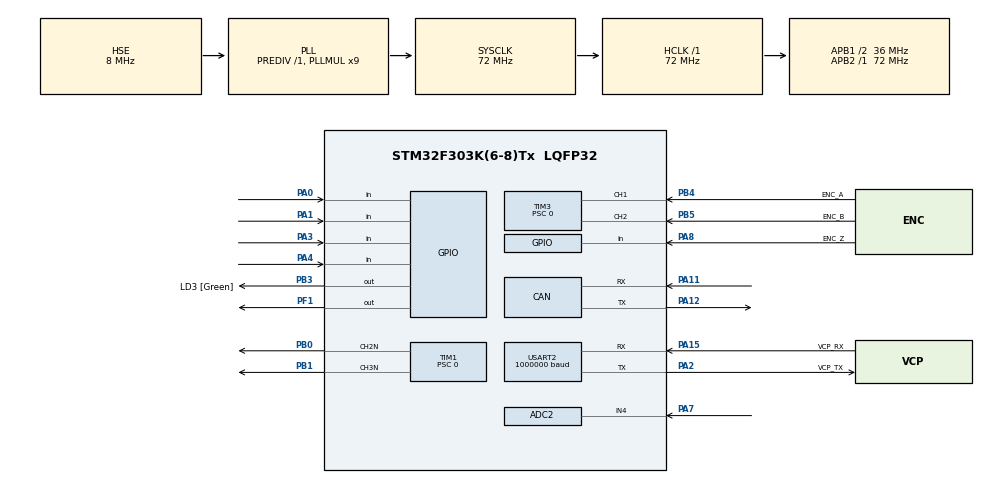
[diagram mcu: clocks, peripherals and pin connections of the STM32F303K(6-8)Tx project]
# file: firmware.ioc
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ADC2.Channel-6\#ChannelRegularConversion=ADC_CHANNEL_4
ADC2.NbrOfConversionFlag=1
ADC2.Offset-6\#ChannelRegularConversion=0
ADC2.OffsetNumber-6\#ChannelRegularConversion=ADC_OFFSET_NONE
ADC2.Rank-6\#ChannelRegularConversion=1
ADC2.SamplingTime-6\#ChannelRegularConversion=ADC_SAMPLETIME_1CYCLE_5
ADC2.SubFamily=STM32F303x8
CAN.BS1=CAN_BS1_1TQ
CAN.BS2=CAN_BS2_1TQ
CAN.CalculateTimeQuantum=444.44444444444446
Dma.Request0=USART2_RX
Dma.USART2_RX.0.Direction=DMA_PERIPH_TO_MEMORY
Dma.USART2_RX.0.Instance=DMA1_Channel6
Dma.USART2_RX.0.MemDataAlignment=DMA_MDATAALIGN_BYTE
Dma.USART2_RX.0.MemInc=DMA_MINC_ENABLE
Dma.USART2_RX.0.Mode=DMA_CIRCULAR
Dma.USART2_RX.0.PeriphDataAlignment=DMA_PDATAALIGN_BYTE
Dma.USART2_RX.0.PeriphInc=DMA_PINC_DISABLE
Dma.USART2_RX.0.Priority=DMA_PRIORITY_LOW
Mcu.Family=STM32F3
Mcu.Name=STM32F303K(6-8)Tx
Mcu.Package=LQFP32
NVIC.DMA1_Channel6_IRQn=true\:0\:0\:false\:false\:true\:false
NVIC.PriorityGroup=NVIC_PRIORITYGROUP_4
PA0.Signal=GPIO_Input
PA1.Signal=GPIO_Input
PA11.Mode=Master
PA11.Signal=CAN_RX
PA12.Mode=Master
PA12.Signal=CAN_TX
PA13.GPIO_Label=SWDIO
PA13.Mode=Serial_Wire
PA13.Signal=SYS_JTMS-SWDIO
PA14.GPIO_Label=SWCLK
PA14.Mode=Serial_Wire
PA14.Signal=SYS_JTCK-SWCLK
PA15.GPIO_Label=VCP_RX
PA15.Mode=Asynchronous
PA15.Signal=USART2_RX
PA2.GPIO_Label=VCP_TX
PA2.Mode=Asynchronous
PA2.Signal=USART2_TX
PA3.Signal=GPIO_Input
PA4.Signal=GPIO_Input
PA7.Mode=IN4-Single-Ended
PA7.Signal=ADC2_IN4
PA8.GPIO_Label=ENC_Z
PA8.Signal=GPIO_Input
PB0.Mode=PWM Generation2 CH2N
PB0.Signal=TIM1_CH2N
PB1.Mode=PWM Generation3 CH3N
PB1.Signal=TIM1_CH3N
PB3.GPIO_Label=LD3 [Green]
PB3.Signal=GPIO_Output
PB4.GPIO_Label=ENC_A
PB4.GPIO_PuPd=GPIO_PULLUP
PB4.Signal=S_TIM3_CH1
PB5.GPIO_Label=ENC_B
PB5.GPIO_PuPd=GPIO_PULLUP
PB5.Signal=S_TIM3_CH2
PF0\ /\ OSC_IN.GPIO_Label=MCO
PF0\ /\ OSC_IN.Mode=HSE-External-Clock-Source
PF0\ /\ OSC_IN.Signal=RCC_OSC_IN
PF1\ /\ OSC_OUT.PinState=GPIO_PIN_SET
PF1\ /\ OSC_OUT.Signal=GPIO_Output
ProjectManager.HeapSize=0x200
ProjectManager.StackSize=0x400
ProjectManager.TargetToolchain=Makefile
RCC.AHBFreq_Value=72000000
RCC.APB1CLKDivider=RCC_HCLK_DIV2
RCC.APB1Freq_Value=36000000
RCC.APB1TimFreq_Value=72000000
RCC.APB2Freq_Value=72000000
RCC.APB2TimFreq_Value=72000000
RCC.CortexFreq_Value=72000000
RCC.EnbaleCSS=true
RCC.HCLKFreq_Value=72000000
RCC.HSE_VALUE=8000000
RCC.HSI_VALUE=8000000
RCC.PLLMUL=RCC_PLL_MUL9
RCC.PLLSourceVirtual=RCC_PLLSOURCE_HSE
RCC.SYSCLKFreq_VALUE=72000000
RCC.SYSCLKSourceVirtual=RCC_SYSCLKSOURCE_PLLCLK
SH.S_TIM3_CH1.0=TIM3_CH1,Encoder_Interface
SH.S_TIM3_CH2.0=TIM3_CH2,Encoder_Interface
TIM1.Channel-PWM\ Generation2\ CH2N=TIM_CHANNEL_2
TIM1.Channel-PWM\ Generation3\ CH3N=TIM_CHANNEL_3
TIM1.Period=7199
TIM1.Prescaler=0
TIM3.EncoderMode=TIM_ENCODERMODE_TI12
TIM3.Period=65535
TIM3.Prescaler=0
USART2.BaudRate=1000000
USART2.DMADisableonRxErrorParam=UART_ADVFEATURE_DMA_DISABLEONRXERROR
USART2.OverSampling=UART_OVERSAMPLING_8
USART2.OverrunDisableParam=UART_ADVFEATURE_OVERRUN_DISABLE
USART2.VirtualMode-Asynchronous=VM_ASYNC
VP_TIM1_VS_ClockSourceINT.Mode=Internal
board=NUCLEO-F303K8

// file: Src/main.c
/* USER CODE BEGIN Header */
/**
  ******************************************************************************
  * @file           : main.c
  * @brief          : Main program body
  ******************************************************************************
  ** This notice applies to any and all portions of this file
  * that are not between comment pairs USER CODE BEGIN and
  * USER CODE END. Other portions of this file, whether
  * inserted by the user or by software development tools
  * are owned by their respective copyright owners.
  *
  * COPYRIGHT(c) 2018 STMicroelectronics
  *
  * Redistribution and use in source and binary forms, with or without modification,
  * are permitted provided that the following conditions are met:
  *   1. Redistributions of source code must retain the above copyright notice,
  *      this list of conditions and the following disclaimer.
  *   2. Redistributions in binary form must reproduce the above copyright notice,
  *      this list of conditions and the following disclaimer in the documentation
  *      and/or other materials provided with the distribution.
  *   3. Neither the name of STMicroelectronics nor the names of its contributors
  *      may be used to endorse or promote products derived from this software
  *      without specific prior written permission.
  *
  * THIS SOFTWARE IS PROVIDED BY THE COPYRIGHT HOLDERS AND CONTRIBUTORS "AS IS"
  * AND ANY EXPRESS OR IMPLIED WARRANTIES, INCLUDING, BUT NOT LIMITED TO, THE
  * IMPLIED WARRANTIES OF MERCHANTABILITY AND FITNESS FOR A PARTICULAR PURPOSE ARE
  * DISCLAIMED. IN NO EVENT SHALL THE COPYRIGHT HOLDER OR CONTRIBUTORS BE LIABLE
  * FOR ANY DIRECT, INDIRECT, INCIDENTAL, SPECIAL, EXEMPLARY, OR CONSEQUENTIAL
  * DAMAGES (INCLUDING, BUT NOT LIMITED TO, PROCUREMENT OF SUBSTITUTE GOODS OR
  * SERVICES; LOSS OF USE, DATA, OR PROFITS; OR BUSINESS INTERRUPTION) HOWEVER
  * CAUSED AND ON ANY THEORY OF LIABILITY, WHETHER IN CONTRACT, STRICT LIABILITY,
  * OR TORT (INCLUDING NEGLIGENCE OR OTHERWISE) ARISING IN ANY WAY OUT OF THE USE
  * OF THIS SOFTWARE, EVEN IF ADVISED OF THE POSSIBILITY OF SUCH DAMAGE.
  *
  ******************************************************************************
  */
/* USER CODE END Header */

#include "main.h"

/* USER CODE BEGIN Includes */
#include "user_main.h"

/* USER CODE END Includes */

ADC_HandleTypeDef hadc2;

CAN_HandleTypeDef hcan;

TIM_HandleTypeDef htim1;
TIM_HandleTypeDef htim3;

UART_HandleTypeDef huart2;
DMA_HandleTypeDef hdma_usart2_rx;

void SystemClock_Config(void);
static void MX_GPIO_Init(void);
static void MX_DMA_Init(void);
static void MX_USART2_UART_Init(void);
static void MX_TIM3_Init(void);
static void MX_CAN_Init(void);
static void MX_TIM1_Init(void);
static void MX_ADC2_Init(void);

int main(void)
{

  /* MCU Configuration--------------------------------------------------------*/

  /* Reset of all peripherals, Initializes the Flash interface and the Systick. */
  HAL_Init();

  /* Configure the system clock */
  SystemClock_Config();

  /* Initialize all configured peripherals */
  MX_GPIO_Init();
  MX_DMA_Init();
  MX_USART2_UART_Init();
  MX_TIM3_Init();
  MX_CAN_Init();
  MX_TIM1_Init();
  MX_ADC2_Init();
  /* USER CODE BEGIN 2 */
  setup();

  /* USER CODE END 2 */

  /* Infinite loop */
  /* USER CODE BEGIN WHILE */
  while (1)
  {
    loop();
    /* USER CODE END WHILE */

  }
}

void SystemClock_Config(void)
{
  RCC_OscInitTypeDef RCC_OscInitStruct = {0};
  RCC_ClkInitTypeDef RCC_ClkInitStruct = {0};
  RCC_PeriphCLKInitTypeDef PeriphClkInit = {0};

  /**Initializes the CPU, AHB and APB busses clocks
  */
  RCC_OscInitStruct.OscillatorType = RCC_OSCILLATORTYPE_HSE;
  RCC_OscInitStruct.HSEState = RCC_HSE_BYPASS;
  RCC_OscInitStruct.HSEPredivValue = RCC_HSE_PREDIV_DIV1;
  RCC_OscInitStruct.HSIState = RCC_HSI_ON;
  RCC_OscInitStruct.PLL.PLLState = RCC_PLL_ON;
  RCC_OscInitStruct.PLL.PLLSource = RCC_PLLSOURCE_HSE;
  RCC_OscInitStruct.PLL.PLLMUL = RCC_PLL_MUL9;
  if (HAL_RCC_OscConfig(&RCC_OscInitStruct) != HAL_OK)
  {
    Error_Handler();
  }
  /**Initializes the CPU, AHB and APB busses clocks
  */
  RCC_ClkInitStruct.ClockType = RCC_CLOCKTYPE_HCLK|RCC_CLOCKTYPE_SYSCLK
                              |RCC_CLOCKTYPE_PCLK1|RCC_CLOCKTYPE_PCLK2;
  RCC_ClkInitStruct.SYSCLKSource = RCC_SYSCLKSOURCE_PLLCLK;
  RCC_ClkInitStruct.AHBCLKDivider = RCC_SYSCLK_DIV1;
  RCC_ClkInitStruct.APB1CLKDivider = RCC_HCLK_DIV2;
  RCC_ClkInitStruct.APB2CLKDivider = RCC_HCLK_DIV1;

  if (HAL_RCC_ClockConfig(&RCC_ClkInitStruct, FLASH_LATENCY_2) != HAL_OK)
  {
    Error_Handler();
  }
  PeriphClkInit.PeriphClockSelection = RCC_PERIPHCLK_TIM1|RCC_PERIPHCLK_ADC12;
  PeriphClkInit.Adc12ClockSelection = RCC_ADC12PLLCLK_DIV1;
  PeriphClkInit.Tim1ClockSelection = RCC_TIM1CLK_HCLK;
  if (HAL_RCCEx_PeriphCLKConfig(&PeriphClkInit) != HAL_OK)
  {
    Error_Handler();
  }
  /**Enables the Clock Security System
  */
  HAL_RCC_EnableCSS();
}

static void MX_ADC2_Init(void)
{

  ADC_ChannelConfTypeDef sConfig = {0};

  /**Common config
  */
  hadc2.Instance = ADC2;
  hadc2.Init.ClockPrescaler = ADC_CLOCK_ASYNC_DIV1;
  hadc2.Init.Resolution = ADC_RESOLUTION_12B;
  hadc2.Init.ScanConvMode = ADC_SCAN_DISABLE;
  hadc2.Init.ContinuousConvMode = DISABLE;
  hadc2.Init.DiscontinuousConvMode = DISABLE;
  hadc2.Init.ExternalTrigConvEdge = ADC_EXTERNALTRIGCONVEDGE_NONE;
  hadc2.Init.ExternalTrigConv = ADC_SOFTWARE_START;
  hadc2.Init.DataAlign = ADC_DATAALIGN_RIGHT;
  hadc2.Init.NbrOfConversion = 1;
  hadc2.Init.DMAContinuousRequests = DISABLE;
  hadc2.Init.EOCSelection = ADC_EOC_SINGLE_CONV;
  hadc2.Init.LowPowerAutoWait = DISABLE;
  hadc2.Init.Overrun = ADC_OVR_DATA_OVERWRITTEN;
  if (HAL_ADC_Init(&hadc2) != HAL_OK)
  {
    Error_Handler();
  }
  /**Configure Regular Channel
  */
  sConfig.Channel = ADC_CHANNEL_4;
  sConfig.Rank = ADC_REGULAR_RANK_1;
  sConfig.SingleDiff = ADC_SINGLE_ENDED;
  sConfig.SamplingTime = ADC_SAMPLETIME_1CYCLE_5;
  sConfig.OffsetNumber = ADC_OFFSET_NONE;
  sConfig.Offset = 0;
  if (HAL_ADC_ConfigChannel(&hadc2, &sConfig) != HAL_OK)
  {
    Error_Handler();
  }

}

static void MX_CAN_Init(void)
{

  hcan.Instance = CAN;
  hcan.Init.Prescaler = 16;
  hcan.Init.Mode = CAN_MODE_NORMAL;
  hcan.Init.SyncJumpWidth = CAN_SJW_1TQ;
  hcan.Init.TimeSeg1 = CAN_BS1_1TQ;
  hcan.Init.TimeSeg2 = CAN_BS2_1TQ;
  hcan.Init.TimeTriggeredMode = DISABLE;
  hcan.Init.AutoBusOff = DISABLE;
  hcan.Init.AutoWakeUp = DISABLE;
  hcan.Init.AutoRetransmission = DISABLE;
  hcan.Init.ReceiveFifoLocked = DISABLE;
  hcan.Init.TransmitFifoPriority = DISABLE;
  if (HAL_CAN_Init(&hcan) != HAL_OK)
  {
    Error_Handler();
  }

}

static void MX_TIM1_Init(void)
{

  TIM_ClockConfigTypeDef sClockSourceConfig = {0};
  TIM_MasterConfigTypeDef sMasterConfig = {0};
  TIM_OC_InitTypeDef sConfigOC = {0};
  TIM_BreakDeadTimeConfigTypeDef sBreakDeadTimeConfig = {0};

  htim1.Instance = TIM1;
  htim1.Init.Prescaler = 1;
  htim1.Init.CounterMode = TIM_COUNTERMODE_UP;
  htim1.Init.Period = 35999;
  htim1.Init.ClockDivision = TIM_CLOCKDIVISION_DIV1;
  htim1.Init.RepetitionCounter = 0;
  htim1.Init.AutoReloadPreload = TIM_AUTORELOAD_PRELOAD_ENABLE;
  if (HAL_TIM_Base_Init(&htim1) != HAL_OK)
  {
    Error_Handler();
  }
  sClockSourceConfig.ClockSource = TIM_CLOCKSOURCE_INTERNAL;
  if (HAL_TIM_ConfigClockSource(&htim1, &sClockSourceConfig) != HAL_OK)
  {
    Error_Handler();
  }
  if (HAL_TIM_PWM_Init(&htim1) != HAL_OK)
  {
    Error_Handler();
  }
  sMasterConfig.MasterOutputTrigger = TIM_TRGO_RESET;
  sMasterConfig.MasterOutputTrigger2 = TIM_TRGO2_RESET;
  sMasterConfig.MasterSlaveMode = TIM_MASTERSLAVEMODE_DISABLE;
  if (HAL_TIMEx_MasterConfigSynchronization(&htim1, &sMasterConfig) != HAL_OK)
  {
    Error_Handler();
  }
  sConfigOC.OCMode = TIM_OCMODE_PWM1;
  sConfigOC.Pulse = 0;
  sConfigOC.OCPolarity = TIM_OCPOLARITY_HIGH;
  sConfigOC.OCNPolarity = TIM_OCNPOLARITY_HIGH;
  sConfigOC.OCFastMode = TIM_OCFAST_DISABLE;
  sConfigOC.OCIdleState = TIM_OCIDLESTATE_RESET;
  sConfigOC.OCNIdleState = TIM_OCNIDLESTATE_RESET;
  if (HAL_TIM_PWM_ConfigChannel(&htim1, &sConfigOC, TIM_CHANNEL_2) != HAL_OK)
  {
    Error_Handler();
  }
  if (HAL_TIM_PWM_ConfigChannel(&htim1, &sConfigOC, TIM_CHANNEL_3) != HAL_OK)
  {
    Error_Handler();
  }
  sBreakDeadTimeConfig.OffStateRunMode = TIM_OSSR_DISABLE;
  sBreakDeadTimeConfig.OffStateIDLEMode = TIM_OSSI_DISABLE;
  sBreakDeadTimeConfig.LockLevel = TIM_LOCKLEVEL_OFF;
  sBreakDeadTimeConfig.DeadTime = 0;
  sBreakDeadTimeConfig.BreakState = TIM_BREAK_DISABLE;
  sBreakDeadTimeConfig.BreakPolarity = TIM_BREAKPOLARITY_HIGH;
  sBreakDeadTimeConfig.BreakFilter = 0;
  sBreakDeadTimeConfig.Break2State = TIM_BREAK2_DISABLE;
  sBreakDeadTimeConfig.Break2Polarity = TIM_BREAK2POLARITY_HIGH;
  sBreakDeadTimeConfig.Break2Filter = 0;
  sBreakDeadTimeConfig.AutomaticOutput = TIM_AUTOMATICOUTPUT_DISABLE;
  if (HAL_TIMEx_ConfigBreakDeadTime(&htim1, &sBreakDeadTimeConfig) != HAL_OK)
  {
    Error_Handler();
  }
  HAL_TIM_MspPostInit(&htim1);

}

static void MX_TIM3_Init(void)
{

  TIM_Encoder_InitTypeDef sConfig = {0};
  TIM_MasterConfigTypeDef sMasterConfig = {0};

  htim3.Instance = TIM3;
  htim3.Init.Prescaler = 0;
  htim3.Init.CounterMode = TIM_COUNTERMODE_UP;
  htim3.Init.Period = 65535;
  htim3.Init.ClockDivision = TIM_CLOCKDIVISION_DIV1;
  htim3.Init.AutoReloadPreload = TIM_AUTORELOAD_PRELOAD_DISABLE;
  sConfig.EncoderMode = TIM_ENCODERMODE_TI12;
  sConfig.IC1Polarity = TIM_ICPOLARITY_RISING;
  sConfig.IC1Selection = TIM_ICSELECTION_DIRECTTI;
  sConfig.IC1Prescaler = TIM_ICPSC_DIV1;
  sConfig.IC1Filter = 0;
  sConfig.IC2Polarity = TIM_ICPOLARITY_RISING;
  sConfig.IC2Selection = TIM_ICSELECTION_DIRECTTI;
  sConfig.IC2Prescaler = TIM_ICPSC_DIV1;
  sConfig.IC2Filter = 0;
  if (HAL_TIM_Encoder_Init(&htim3, &sConfig) != HAL_OK)
  {
    Error_Handler();
  }
  sMasterConfig.MasterOutputTrigger = TIM_TRGO_RESET;
  sMasterConfig.MasterSlaveMode = TIM_MASTERSLAVEMODE_DISABLE;
  if (HAL_TIMEx_MasterConfigSynchronization(&htim3, &sMasterConfig) != HAL_OK)
  {
    Error_Handler();
  }

}

static void MX_USART2_UART_Init(void)
{

  huart2.Instance = USART2;
  huart2.Init.BaudRate = 1000000;
  huart2.Init.WordLength = UART_WORDLENGTH_8B;
  huart2.Init.StopBits = UART_STOPBITS_1;
  huart2.Init.Parity = UART_PARITY_NONE;
  huart2.Init.Mode = UART_MODE_TX_RX;
  huart2.Init.HwFlowCtl = UART_HWCONTROL_NONE;
  huart2.Init.OverSampling = UART_OVERSAMPLING_8;
  huart2.Init.OneBitSampling = UART_ONE_BIT_SAMPLE_DISABLE;
  huart2.AdvancedInit.AdvFeatureInit = UART_ADVFEATURE_RXOVERRUNDISABLE_INIT|UART_ADVFEATURE_DMADISABLEONERROR_INIT;
  huart2.AdvancedInit.OverrunDisable = UART_ADVFEATURE_OVERRUN_DISABLE;
  huart2.AdvancedInit.DMADisableonRxError = UART_ADVFEATURE_DMA_DISABLEONRXERROR;
  if (HAL_UART_Init(&huart2) != HAL_OK)
  {
    Error_Handler();
  }

}

static void MX_DMA_Init(void)
{
  /* DMA controller clock enable */
  __HAL_RCC_DMA1_CLK_ENABLE();

  /* DMA interrupt init */
  /* DMA1_Channel6_IRQn interrupt configuration */
  HAL_NVIC_SetPriority(DMA1_Channel6_IRQn, 0, 0);
  HAL_NVIC_EnableIRQ(DMA1_Channel6_IRQn);

}

static void MX_GPIO_Init(void)
{
  GPIO_InitTypeDef GPIO_InitStruct = {0};

  /* GPIO Ports Clock Enable */
  __HAL_RCC_GPIOF_CLK_ENABLE();
  __HAL_RCC_GPIOA_CLK_ENABLE();
  __HAL_RCC_GPIOB_CLK_ENABLE();

  /*Configure GPIO pin Output Level */
  HAL_GPIO_WritePin(GPIOF, GPIO_PIN_1, GPIO_PIN_SET);

  /*Configure GPIO pin Output Level */
  HAL_GPIO_WritePin(LD3_GPIO_Port, LD3_Pin, GPIO_PIN_RESET);

  /*Configure GPIO pin : PF1 */
  GPIO_InitStruct.Pin = GPIO_PIN_1;
  GPIO_InitStruct.Mode = GPIO_MODE_OUTPUT_PP;
  GPIO_InitStruct.Pull = GPIO_NOPULL;
  GPIO_InitStruct.Speed = GPIO_SPEED_FREQ_LOW;
  HAL_GPIO_Init(GPIOF, &GPIO_InitStruct);

  /*Configure GPIO pins : PA0 PA1 PA3 PA4
                           ENC_Z_Pin */
  GPIO_InitStruct.Pin = GPIO_PIN_0|GPIO_PIN_1|GPIO_PIN_3|GPIO_PIN_4
                          |ENC_Z_Pin;
  GPIO_InitStruct.Mode = GPIO_MODE_INPUT;
  GPIO_InitStruct.Pull = GPIO_NOPULL;
  HAL_GPIO_Init(GPIOA, &GPIO_InitStruct);

  /*Configure GPIO pin : LD3_Pin */
  GPIO_InitStruct.Pin = LD3_Pin;
  GPIO_InitStruct.Mode = GPIO_MODE_OUTPUT_PP;
  GPIO_InitStruct.Pull = GPIO_NOPULL;
  GPIO_InitStruct.Speed = GPIO_SPEED_FREQ_LOW;
  HAL_GPIO_Init(LD3_GPIO_Port, &GPIO_InitStruct);

}

void Error_Handler(void)
{
}

/************************ (C) COPYRIGHT STMicroelectronics *****END OF FILE****/
